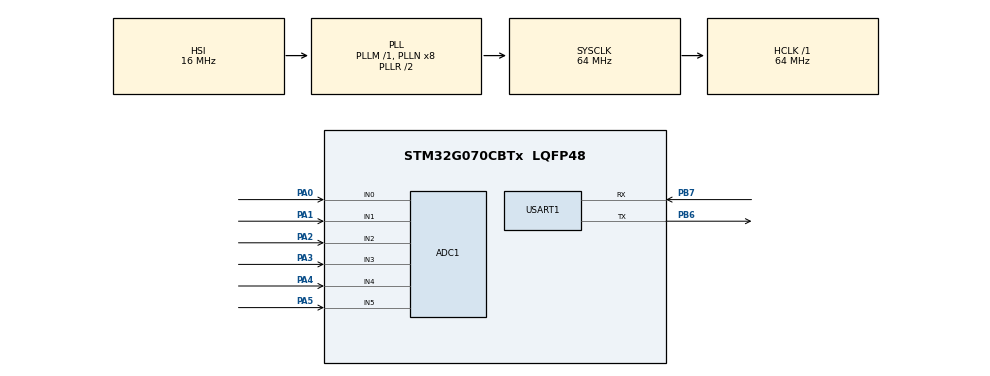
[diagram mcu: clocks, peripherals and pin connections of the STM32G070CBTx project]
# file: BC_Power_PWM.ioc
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ADC1.Channel-0\#ChannelRegularConversion=ADC_CHANNEL_0
ADC1.Channel-1\#ChannelRegularConversion=ADC_CHANNEL_1
ADC1.Channel-2\#ChannelRegularConversion=ADC_CHANNEL_2
ADC1.Channel-3\#ChannelRegularConversion=ADC_CHANNEL_3
ADC1.Channel-4\#ChannelRegularConversion=ADC_CHANNEL_4
ADC1.Channel-5\#ChannelRegularConversion=ADC_CHANNEL_5
ADC1.ContinuousConvMode=ENABLE
ADC1.DMAContinuousRequests=ENABLE
ADC1.NbrOfConversion=6
ADC1.NbrOfConversionFlag=1
ADC1.Overrun=ADC_OVR_DATA_OVERWRITTEN
ADC1.OversamplingMode=ENABLE
ADC1.Rank-0\#ChannelRegularConversion=1
ADC1.Rank-1\#ChannelRegularConversion=2
ADC1.Rank-2\#ChannelRegularConversion=3
ADC1.Rank-3\#ChannelRegularConversion=4
ADC1.Rank-4\#ChannelRegularConversion=5
ADC1.Rank-5\#ChannelRegularConversion=6
ADC1.Ratio=ADC_OVERSAMPLING_RATIO_32
ADC1.RightBitShift=ADC_RIGHTBITSHIFT_5
ADC1.SamplingTime-0\#ChannelRegularConversion=ADC_SAMPLINGTIME_COMMON_1
ADC1.SamplingTime-1\#ChannelRegularConversion=ADC_SAMPLINGTIME_COMMON_1
ADC1.SamplingTime-2\#ChannelRegularConversion=ADC_SAMPLINGTIME_COMMON_1
ADC1.SamplingTime-3\#ChannelRegularConversion=ADC_SAMPLINGTIME_COMMON_1
ADC1.SamplingTime-4\#ChannelRegularConversion=ADC_SAMPLINGTIME_COMMON_1
ADC1.SamplingTime-5\#ChannelRegularConversion=ADC_SAMPLINGTIME_COMMON_1
ADC1.SamplingTimeCommon1=ADC_SAMPLETIME_12CYCLES_5
ADC1.SamplingTimeCommon2=ADC_SAMPLETIME_12CYCLES_5
ADC1.SelectedChannel=ADC_CHANNEL_0|ADC_CHANNEL_1|ADC_CHANNEL_2|ADC_CHANNEL_3|ADC_CHANNEL_4|ADC_CHANNEL_5
ADC1.master=1
Dma.ADC1.2.Direction=DMA_PERIPH_TO_MEMORY
Dma.ADC1.2.EventEnable=DISABLE
Dma.ADC1.2.Instance=DMA1_Channel3
Dma.ADC1.2.MemDataAlignment=DMA_MDATAALIGN_HALFWORD
Dma.ADC1.2.MemInc=DMA_MINC_ENABLE
Dma.ADC1.2.Mode=DMA_NORMAL
Dma.ADC1.2.PeriphDataAlignment=DMA_PDATAALIGN_HALFWORD
Dma.ADC1.2.PeriphInc=DMA_PINC_DISABLE
Dma.ADC1.2.Polarity=HAL_DMAMUX_REQ_GEN_RISING
Dma.ADC1.2.Priority=DMA_PRIORITY_LOW
Dma.ADC1.2.RequestNumber=1
Dma.ADC1.2.SignalID=NONE
Dma.ADC1.2.SyncEnable=DISABLE
Dma.ADC1.2.SyncPolarity=HAL_DMAMUX_SYNC_NO_EVENT
Dma.ADC1.2.SyncRequestNumber=1
Dma.ADC1.2.SyncSignalID=NONE
Dma.Request0=USART1_RX
Dma.Request1=USART1_TX
Dma.Request2=ADC1
Dma.USART1_RX.0.Direction=DMA_PERIPH_TO_MEMORY
Dma.USART1_RX.0.EventEnable=DISABLE
Dma.USART1_RX.0.Instance=DMA1_Channel1
Dma.USART1_RX.0.MemDataAlignment=DMA_MDATAALIGN_BYTE
Dma.USART1_RX.0.MemInc=DMA_MINC_ENABLE
Dma.USART1_RX.0.Mode=DMA_NORMAL
Dma.USART1_RX.0.PeriphDataAlignment=DMA_PDATAALIGN_BYTE
Dma.USART1_RX.0.PeriphInc=DMA_PINC_DISABLE
Dma.USART1_RX.0.Polarity=HAL_DMAMUX_REQ_GEN_RISING
Dma.USART1_RX.0.Priority=DMA_PRIORITY_LOW
Dma.USART1_RX.0.RequestNumber=1
Dma.USART1_RX.0.SignalID=NONE
Dma.USART1_RX.0.SyncEnable=DISABLE
Dma.USART1_RX.0.SyncPolarity=HAL_DMAMUX_SYNC_NO_EVENT
Dma.USART1_RX.0.SyncRequestNumber=1
Dma.USART1_RX.0.SyncSignalID=NONE
Dma.USART1_TX.1.Direction=DMA_MEMORY_TO_PERIPH
Dma.USART1_TX.1.EventEnable=DISABLE
Dma.USART1_TX.1.Instance=DMA1_Channel2
Dma.USART1_TX.1.MemDataAlignment=DMA_MDATAALIGN_BYTE
Dma.USART1_TX.1.MemInc=DMA_MINC_ENABLE
Dma.USART1_TX.1.Mode=DMA_NORMAL
Dma.USART1_TX.1.PeriphDataAlignment=DMA_PDATAALIGN_BYTE
Dma.USART1_TX.1.PeriphInc=DMA_PINC_DISABLE
Dma.USART1_TX.1.Polarity=HAL_DMAMUX_REQ_GEN_RISING
Dma.USART1_TX.1.Priority=DMA_PRIORITY_LOW
Dma.USART1_TX.1.RequestNumber=1
Dma.USART1_TX.1.SignalID=NONE
Dma.USART1_TX.1.SyncEnable=DISABLE
Dma.USART1_TX.1.SyncPolarity=HAL_DMAMUX_SYNC_NO_EVENT
Dma.USART1_TX.1.SyncRequestNumber=1
Dma.USART1_TX.1.SyncSignalID=NONE
Mcu.Family=STM32G0
Mcu.Name=STM32G070CBTx
Mcu.Package=LQFP48
NVIC.DMA1_Channel1_IRQn=true\:0\:0\:false\:false\:true\:false\:true\:true
NVIC.DMA1_Channel2_3_IRQn=true\:0\:0\:false\:false\:true\:false\:true\:true
NVIC.USART1_IRQn=true\:0\:0\:false\:false\:true\:true\:true\:true
PA0.Mode=IN0
PA0.Signal=ADC1_IN0
PA1.Mode=IN1
PA1.Signal=ADC1_IN1
PA2.Mode=IN2
PA2.Signal=ADC1_IN2
PA3.Mode=IN3
PA3.Signal=ADC1_IN3
PA4.Mode=IN4
PA4.Signal=ADC1_IN4
PA5.Mode=IN5
PA5.Signal=ADC1_IN5
PB6.Mode=Asynchronous
PB6.Signal=USART1_TX
PB7.Mode=Asynchronous
PB7.Signal=USART1_RX
PF0-OSC_IN\ (PF0).Mode=HSE-External-Oscillator
PF0-OSC_IN\ (PF0).Signal=RCC_OSC_IN
PF1-OSC_OUT\ (PF1).Mode=HSE-External-Oscillator
PF1-OSC_OUT\ (PF1).Signal=RCC_OSC_OUT
ProjectManager.HeapSize=0x200
ProjectManager.StackSize=0x400
ProjectManager.TargetToolchain=STM32CubeIDE
RCC.ADCFreq_Value=64000000
RCC.AHBFreq_Value=64000000
RCC.CortexFreq_Value=64000000
RCC.EXTERNAL_CLOCK_VALUE=48000
RCC.HCLKFreq_Value=64000000
RCC.HSE_VALUE=8000000
RCC.HSI_VALUE=16000000
RCC.LSE_VALUE=32768
RCC.SYSCLKFreq_VALUE=64000000
RCC.SYSCLKSource=RCC_SYSCLKSOURCE_PLLCLK
RCC.VCOOutputFreq_Value=128000000
USART1.VirtualMode-Asynchronous=VM_ASYNC
VP_SYS_VS_DBSignals.Mode=DisableDeadBatterySignals
board=custom

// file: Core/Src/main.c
/* USER CODE BEGIN Header */
/**
  ******************************************************************************
  * @file           : main.c
  * @brief          : Main program body
  ******************************************************************************
  * @attention
  *
  * Copyright (c) 2024 STMicroelectronics.
  * All rights reserved.
  *
  * This software is licensed under terms that can be found in the LICENSE file
  * in the root directory of this software component.
  * If no LICENSE file comes with this software, it is provided AS-IS.
  *
  ******************************************************************************
  */
/* USER CODE END Header */
#include "main.h"
#include "adc.h"
#include "dma.h"
#include "usart.h"
#include "gpio.h"

/* USER CODE BEGIN Includes */
#include "app_core.h"
/* USER CODE END Includes */

void SystemClock_Config(void);

int main(void)
{

  /* MCU Configuration--------------------------------------------------------*/

  /* Reset of all peripherals, Initializes the Flash interface and the Systick. */
  HAL_Init();

  /* Configure the system clock */
  SystemClock_Config();

  /* Initialize all configured peripherals */
  MX_GPIO_Init();
  MX_DMA_Init();
  MX_USART1_UART_Init();
  MX_ADC1_Init();

  /* Infinite loop */
  /* USER CODE BEGIN WHILE */
  app_core();
  while (1)
  {
    /* USER CODE END WHILE */

  }
}

void SystemClock_Config(void)
{
  RCC_OscInitTypeDef RCC_OscInitStruct = {0};
  RCC_ClkInitTypeDef RCC_ClkInitStruct = {0};

  /** Configure the main internal regulator output voltage
  */
  HAL_PWREx_ControlVoltageScaling(PWR_REGULATOR_VOLTAGE_SCALE1);

  /** Initializes the RCC Oscillators according to the specified parameters
  * in the RCC_OscInitTypeDef structure.
  */
  RCC_OscInitStruct.OscillatorType = RCC_OSCILLATORTYPE_HSI;
  RCC_OscInitStruct.HSIState = RCC_HSI_ON;
  RCC_OscInitStruct.HSIDiv = RCC_HSI_DIV1;
  RCC_OscInitStruct.HSICalibrationValue = RCC_HSICALIBRATION_DEFAULT;
  RCC_OscInitStruct.PLL.PLLState = RCC_PLL_ON;
  RCC_OscInitStruct.PLL.PLLSource = RCC_PLLSOURCE_HSI;
  RCC_OscInitStruct.PLL.PLLM = RCC_PLLM_DIV1;
  RCC_OscInitStruct.PLL.PLLN = 8;
  RCC_OscInitStruct.PLL.PLLP = RCC_PLLP_DIV2;
  RCC_OscInitStruct.PLL.PLLR = RCC_PLLR_DIV2;
  if (HAL_RCC_OscConfig(&RCC_OscInitStruct) != HAL_OK)
  {
    Error_Handler();
  }

  /** Initializes the CPU, AHB and APB buses clocks
  */
  RCC_ClkInitStruct.ClockType = RCC_CLOCKTYPE_HCLK|RCC_CLOCKTYPE_SYSCLK
                              |RCC_CLOCKTYPE_PCLK1;
  RCC_ClkInitStruct.SYSCLKSource = RCC_SYSCLKSOURCE_PLLCLK;
  RCC_ClkInitStruct.AHBCLKDivider = RCC_SYSCLK_DIV1;
  RCC_ClkInitStruct.APB1CLKDivider = RCC_HCLK_DIV1;

  if (HAL_RCC_ClockConfig(&RCC_ClkInitStruct, FLASH_LATENCY_2) != HAL_OK)
  {
    Error_Handler();
  }
}

void Error_Handler(void)
{
  __disable_irq();
  while (1)
  {
  }
}
